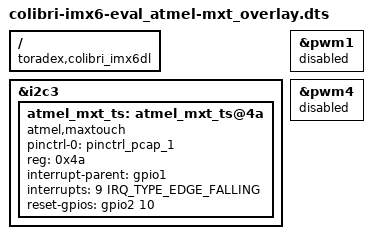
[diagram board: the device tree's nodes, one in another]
// Atmel touchscreen for the 7inch and 10inch display orderable at Toradex. Use this devicetree on the Evaluation or Iris board.

/dts-v1/;
/plugin/;

#include <dt-bindings/gpio/gpio.h>
#include <dt-bindings/interrupt-controller/irq.h>

/ {
	compatible = "toradex,colibri_imx6dl";
};

&i2c3 {
	#address-cells = <1>;
	#size-cells = <0>;

	/* Atmel maxtouch controller */
	atmel_mxt_ts: atmel_mxt_ts@4a {
		compatible = "atmel,maxtouch";
		pinctrl-names = "default";
		pinctrl-0 = <&pinctrl_pcap_1>;
		reg = <0x4a>;
		interrupt-parent = <&gpio1>;
		interrupts = <9 IRQ_TYPE_EDGE_FALLING>;
		reset-gpios = <&gpio2 10 GPIO_ACTIVE_HIGH>;
	};
};

&pwm1 {
	status = "disabled";
};

&pwm4{
	status = "disabled";
};
